# STM32F7x6 register map
File version: 1.6
CPU: CM7 r0p1, little endian, MPU, FPU, 4 interrupt priority bits
Registers are 32-bit, read-write, reset 0x0 unless marked. A register's access mark holds for its fields unless they carry their own. Offsets are from the block's base; [hi:lo] are bit positions; lines under a group give offsets from that group; {n}, {i} and the like mark numbered series; 'fields as' and 'values as' point back to an identical list.

## ADC1 — Analog-to-digital converter
Base 0x40012000
Same registers: ADC2 0x40012100, ADC3 0x40012200
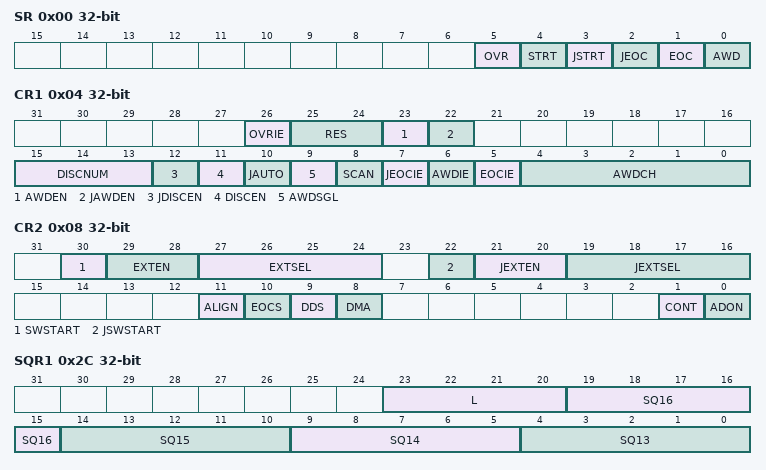
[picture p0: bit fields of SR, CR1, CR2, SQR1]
0x00 SR — status register
  [5] OVR — Overrun
  [4] STRT write-0-clears — Regular channel start flag
    on read: 0=NotStarted (No regular channel conversion started); 1=Started (Regular channel conversion has started) | on write: 0=Clear flag
  [3] JSTRT write-0-clears — Injected channel start flag
    on read: 0=NotStarted (No injected channel conversion started); 1=Started (Injected channel conversion has started) | on write: 0=Clear flag
  [2] JEOC write-0-clears — Injected channel end of conversion
    on read: 0=NotComplete (Conversion is not complete); 1=Complete (Conversion complete) | on write: 0=Clear flag
  [1] EOC write-0-clears — Regular channel end of conversion
    values as JEOC
  [0] AWD write-0-clears — Analog watchdog flag
    on read: 0=NoEvent (No analog watchdog event occurred); 1=Event (Analog watchdog event occurred) | on write: 0=Clear flag
0x04 CR1 — control register 1
  [26] OVRIE — Overrun interrupt enable
    0=Disabled (Overrun interrupt disabled); 1=Enabled (Overrun interrupt enabled)
  [25:24] RES — Resolution
    0=TwelveBit (12-bit (15 ADCCLK cycles)); 1=TenBit (10-bit (13 ADCCLK cycles)); 2=EightBit (8-bit (11 ADCCLK cycles)); 3=SixBit (6-bit (9 ADCCLK cycles))
  [23] AWDEN — Analog watchdog enable on regular channels
    0=Disabled (Analog watchdog disabled on regular channels); 1=Enabled (Analog watchdog enabled on regular channels)
  [22] JAWDEN — Analog watchdog enable on injected channels
    0=Disabled (Analog watchdog disabled on injected channels); 1=Enabled (Analog watchdog enabled on injected channels)
  [15:13] DISCNUM — Discontinuous mode channel count
  [12] JDISCEN — Discontinuous mode on injected channels
    0=Disabled (Discontinuous mode on injected channels disabled); 1=Enabled (Discontinuous mode on injected channels enabled)
  [11] DISCEN — Discontinuous mode on regular channels
    0=Disabled (Discontinuous mode on regular channels disabled); 1=Enabled (Discontinuous mode on regular channels enabled)
  [10] JAUTO — Automatic injected group conversion
    0=Disabled (Automatic injected group conversion disabled); 1=Enabled (Automatic injected group conversion enabled)
  [9] AWDSGL — Enable the watchdog on a single channel in scan mode
    0=AllChannels (Analog watchdog enabled on all channels); 1=SingleChannel (Analog watchdog enabled on a single channel)
  [8] SCAN — Scan mode
    0=Disabled (Scan mode disabled); 1=Enabled (Scan mode enabled)
  [7] JEOCIE — Interrupt enable for injected channels
    0=Disabled (JEOC interrupt disabled); 1=Enabled (JEOC interrupt enabled)
  [6] AWDIE — Analog watchdog interrupt enable
    0=Disabled (Analogue watchdog interrupt disabled); 1=Enabled (Analogue watchdog interrupt enabled)
  [5] EOCIE — Interrupt enable for EOC
    0=Disabled (EOC interrupt disabled); 1=Enabled (EOC interrupt enabled)
  [4:0] AWDCH range 0..18 — Analog watchdog channel select bits
0x08 CR2 — control register 2
  [30] SWSTART — Start conversion of regular channels
    on write: 1=Starts conversion of regular channels
  [29:28] EXTEN — External trigger enable for regular channels
    0=Disabled (Trigger detection disabled); 1=RisingEdge (Trigger detection on the rising edge); 2=FallingEdge (Trigger detection on the falling edge); 3=BothEdges (Trigger detection on both the rising and falling edges)
  [27:24] EXTSEL — External event select for regular group
    0=TIM1CH1 (Timer 1 CH1); 1=TIM1CH2 (Timer 1 CH2); 2=TIM1CH3 (Timer 1 CH3); 3=TIM2CH2 (Timer 2 CH2); 4=TIM5TRGO (Timer 5 TRGO); 5=TIM4CH4 (Timer 4 CH4); 6=TIM3CH4 (Timer 3 CH4); 7=TIM8TRGO (Timer 8 TRGO); 8=TIM8TRGO2 (Timer 8 TRGO(2)); 9=TIM1TRGO (Timer 1 TRGO); 10=TIM1TRGO2 (Timer 1 TRGO(2)); 11=TIM2TRGO (Timer 2 TRGO); 12=TIM4TRGO (Timer 4 TRGO); 13=TIM6TRGO (Timer 6 TRGO); 15=EXTI11 (EXTI line 11)
  [22] JSWSTART — Start conversion of injected channels
    on write: 1=Starts conversion of injected channels
  [21:20] JEXTEN — External trigger enable for injected channels
    values as EXTEN
  [19:16] JEXTSEL — External event select for injected group
    0=TIM1TRGO (Timer 1 TRGO); 1=TIM1CH4 (Timer 1 CH4); 2=TIM2TRGO (Timer 2 TRGO); 3=TIM2CH1 (Timer 2 CH1); 4=TIM3CH4 (Timer 3 CH4); 5=TIM4TRGO (Timer 4 TRGO); 7=TIM8CH4 (Timer 8 CH4); 8=TIM1TRGO2 (Timer 1 TRGO(2)); 9=TIM8TRGO (Timer 8 TRGO); 10=TIM8TRGO2 (Timer 8 TRGO(2)); 11=TIM3CH3 (Timer 3 CH3); 12=TIM5TRGO (Timer 5 TRGO); 13=TIM3CH1 (Timer 3 CH1); 14=TIM6TRGO (Timer 6 TRGO)
  [11] ALIGN — Data alignment
    0=Right alignment; 1=Left alignment
  [10] EOCS — End of conversion selection
    0=EachSequence (The EOC bit is set at the end of each sequence of regular conversions); 1=EachConversion (The EOC bit is set at the end of each regular conversion)
  [9] DDS — DMA disable selection (for single ADC mode)
    0=Single (No new DMA request is issued after the last transfer); 1=Continuous (DMA requests are issued as long as data are converted and DMA=1)
  [8] DMA — Direct memory access mode (for single ADC mode)
    0=Disabled (DMA mode disabled); 1=Enabled (DMA mode enabled)
  [1] CONT — Continuous conversion
    0=Single conversion mode; 1=Continuous conversion mode
  [0] ADON — A/D Converter ON / OFF
    0=Disabled (Disable ADC conversion and go to power down mode); 1=Enabled (Enable ADC)
0x0C SMPR1 — sample time register 1
  [31:0] SMPx_x — Sample time bits
    0=Cycles3 (3 cycles); 1=Cycles15 (15 cycles); 2=Cycles28 (28 cycles); 3=Cycles56 (56 cycles); 4=Cycles84 (84 cycles); 5=Cycles112 (112 cycles); 6=Cycles144 (144 cycles); 7=Cycles480 (480 cycles)
0x10 SMPR2 — sample time register 2
  fields as SMPR1
{0x10+4i} JOFR{i} (i=1..4) — injected channel data offset register x
  [11:0] JOFFSET — Data offset for injected channel x
0x24 HTR reset 0xFFF — watchdog higher threshold register
  [11:0] HT — Analog watchdog higher threshold
0x28 LTR — watchdog lower threshold register
  [11:0] LT — Analog watchdog lower threshold
0x2C SQR1 — regular sequence register 1
  [23:20] L — Regular channel sequence length
  [5n-61:5n-65] SQ{n} range 0..18 (n=13..16) — {n}th conversion in regular sequence
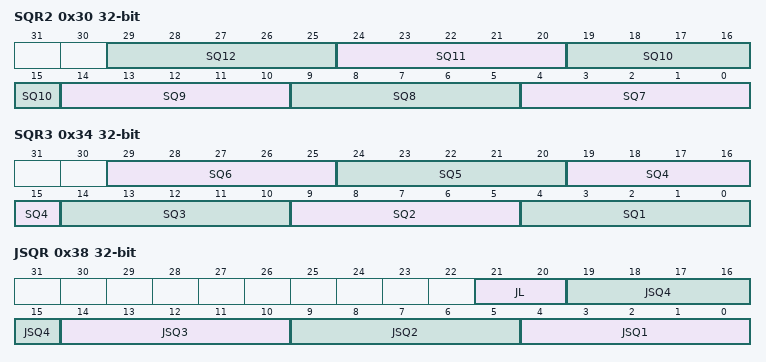
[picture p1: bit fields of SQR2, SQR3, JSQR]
0x30 SQR2 — regular sequence register 2
  [5n-31:5n-35] SQ{n} range 0..18 (n=7..12) — {n}th conversion in regular sequence
0x34 SQR3 — regular sequence register 3
  [29:25] SQ6 range 0..18 — 6th conversion in regular sequence
  [24:20] SQ5 range 0..18 — 5th conversion in regular sequence
  [19:15] SQ4 range 0..18 — 4th conversion in regular sequence
  [14:10] SQ3 range 0..18 — 3rd conversion in regular sequence
  [9:5] SQ2 range 0..18 — 2nd conversion in regular sequence
  [4:0] SQ1 range 0..18 — 1st conversion in regular sequence
0x38 JSQR — injected sequence register
  [21:20] JL — Injected sequence length
  [19:15] JSQ4 range 0..18 — 4th conversion in injected sequence
  [14:10] JSQ3 range 0..18 — 3rd conversion in injected sequence
  [9:5] JSQ2 range 0..18 — 2nd conversion in injected sequence
  [4:0] JSQ1 range 0..18 — 1st conversion in injected sequence
{0x38+4i} JDR{i} (i=1..4) ro — injected data register x
  [15:0] JDATA — Injected data
0x4C DR ro — regular data register
  [15:0] DATA — Regular data
